VERSION ""

NS_ :

BS_:

BU_: UI BMU

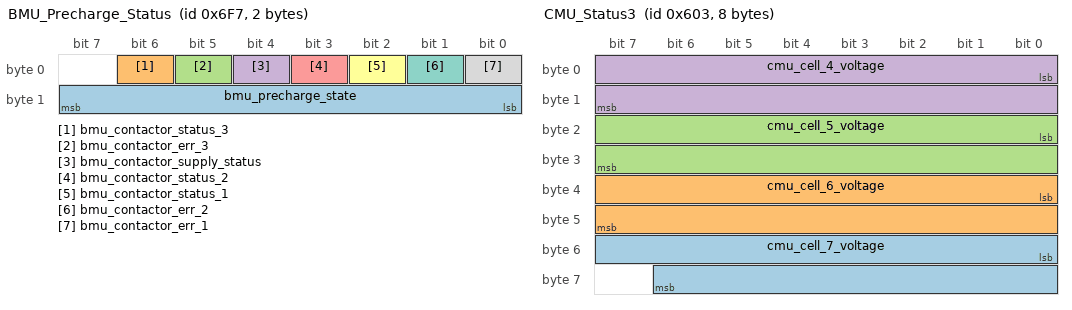
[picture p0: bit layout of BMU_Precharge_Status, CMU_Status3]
BO_ 1783 BMU_Precharge_Status: 2 BMU
 SG_ bmu_precharge_state : 8|8@1+ (1,0) [0|5] "enum" Vector__XXX
 SG_ bmu_contactor_status_3 : 6|1@1+ (1,0) [0|1] "flag" Vector__XXX
 SG_ bmu_contactor_err_3 : 5|1@1+ (1,0) [0|1] "flag" Vector__XXX
 SG_ bmu_contactor_supply_status : 4|1@1+ (1,0) [0|1] "flag" Vector__XXX
 SG_ bmu_contactor_status_2 : 3|1@1+ (1,0) [0|1] "flag" Vector__XXX
 SG_ bmu_contactor_status_1 : 2|1@1+ (1,0) [0|1] "flag" Vector__XXX
 SG_ bmu_contactor_err_2 : 1|1@1+ (1,0) [0|1] "flag" Vector__XXX
 SG_ bmu_contactor_err_1 : 0|1@1+ (1,0) [0|1] "flag" Vector__XXX

BO_ 1781 BMU_Balance_SOC: 8 BMU
 SG_ bmu_bal_soc_percent : 32|32@1- (1,0) [0|0] "%" Vector__XXX
 SG_ bmu_bal_soc_ah : 0|32@1- (1,0) [0|0] "Ah" Vector__XXX

BO_ 1780 BMU_SOC: 8 BMU
 SG_ bmu_soc_percent : 32|32@1- (1,0) [0|0] "%" Vector__XXX
 SG_ bmu_soc_ah : 0|32@1- (1,0) [0|0] "Ah" Vector__XXX

BO_ 1539 CMU_Status3: 8 BMU
 SG_ cmu_cell_7_voltage : 48|15@1- (1,0) [0|0] "mV"  UI
 SG_ cmu_cell_6_voltage : 32|16@1- (1,0) [0|0] "mV"  UI
 SG_ cmu_cell_5_voltage : 16|16@1- (1,0) [0|0] "mV"  UI
 SG_ cmu_cell_4_voltage : 0|16@1- (1,0) [0|0] "mV"  UI

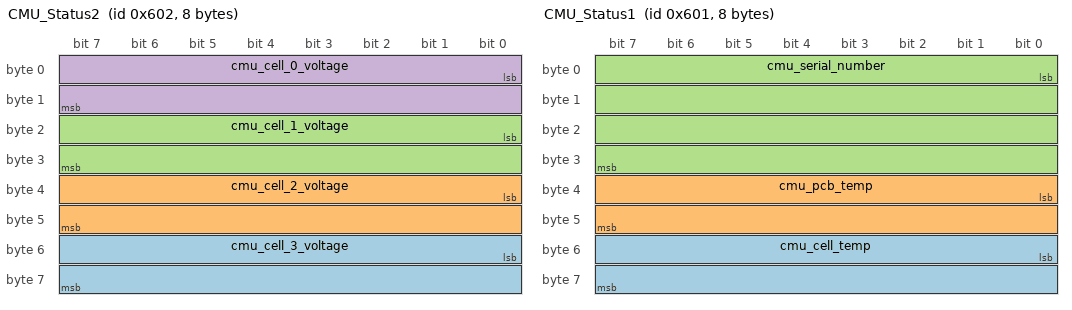
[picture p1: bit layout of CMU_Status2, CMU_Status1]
BO_ 1538 CMU_Status2: 8 BMU
 SG_ cmu_cell_3_voltage : 48|16@1- (1,0) [0|0] "mV"  UI
 SG_ cmu_cell_2_voltage : 32|16@1- (1,0) [0|0] "mV"  UI
 SG_ cmu_cell_1_voltage : 16|16@1- (1,0) [0|0] "mV"  UI
 SG_ cmu_cell_0_voltage : 0|16@1- (1,0) [0|0] "mV"  UI

BO_ 1537 CMU_Status1: 8 BMU
 SG_ cmu_cell_temp : 48|16@1- (0.1,0) [0|0] "°C"  UI
 SG_ cmu_pcb_temp : 32|16@1- (0.1,0) [0|0] "°C" Vector__XXX
 SG_ cmu_serial_number : 0|32@1+ (1,0) [0|0] "" Vector__XXX

BO_ 1536 BMU_Heartbeat: 8 BMU
 SG_ bmu_verison_number : 0|32@1+ (1,0) [0|0] "" Vector__XXX
 SG_ bmu_serial_number : 32|32@1+ (1,0) [0|0] "" Vector__XXX

EV_ test: 0 [0|0] "" 0 1 DUMMY_NODE_VECTOR0 Vector__XXX;

CM_ SG_ 1783 bmu_precharge_state "0 = Error, 1 = Idle, 5 = Enable Pack, 2 = Measure, 3 = Precharge, 4 = Run";
CM_ SG_ 1783 bmu_contactor_status_3 "0 = Off, 1 = On";
CM_ SG_ 1783 bmu_contactor_err_3 "0 = OK, 1 = error";
CM_ SG_ 1783 bmu_contactor_supply_status "0 = Fault, 1 = OK";
CM_ SG_ 1783 bmu_contactor_status_2 "0 = Off, 1 = On
";
CM_ SG_ 1783 bmu_contactor_status_1 "0 = Off, 1 = On";
CM_ SG_ 1783 bmu_contactor_err_2 "0 = OK, 1 = error";
CM_ SG_ 1783 bmu_contactor_err_1 "0 = OK, 1 = error";
CM_ SG_ 1781 bmu_bal_soc_percent "Shows the balancing SOC as a percentage, in other words, the percentage mismatch between cells this session.";
CM_ SG_ 1781 bmu_bal_soc_ah "Shows Ah supplied to the pack since the first cell began balancing. This number will continue to count up until all cells in the pack are balancing, therefore showing the Ah mismatch that has been corrected during this balancing session.";
CM_ BO_ 1780 "Interval: 1 Hz";
CM_ SG_ 1780 bmu_soc_percent "Shows the SOC as a percentage. 100% = full, 0% = empty";
CM_ SG_ 1780 bmu_soc_ah "SOC (Ah). Shows Ah consumed from the pack. 0 = Full, and counts upwards towards the user-set pack capacity number as Ah are used. Resets to 0 when max cell reaches balance threshold.";
CM_ BO_ 1539 "Interval: 1 Hz";
CM_ SG_ 1539 cmu_cell_7_voltage "+ve = OK, -ve = channel mismatch";
CM_ SG_ 1539 cmu_cell_6_voltage "+ve = OK, -ve = channel mismatch";
CM_ SG_ 1539 cmu_cell_5_voltage "+ve = OK, -ve = channel mismatch";
CM_ SG_ 1539 cmu_cell_4_voltage "+ve = OK, -ve = channel mismatch";
CM_ BO_ 1538 "Interval: 1 Hz";
CM_ SG_ 1538 cmu_cell_3_voltage "+ve = OK, -ve = channel mismatch";
CM_ SG_ 1538 cmu_cell_2_voltage "+ve = OK, -ve = channel mismatch";
CM_ SG_ 1538 cmu_cell_1_voltage "+ve = OK, -ve = channel mismatch";
CM_ SG_ 1538 cmu_cell_0_voltage "+ve = OK, -ve = channel mismatch";
CM_ BO_ 1537 "Interval: Approx 1 Hz";
CM_ SG_ 1537 cmu_cell_temp "Cell temperature ( 1/10th °C)";
CM_ SG_ 1537 cmu_pcb_temp "PCB temperature ( 1/10th °C)";
CM_ SG_ 1537 cmu_serial_number "CMU serial number (allocated at factory)";
CM_ BO_ 1536 "Interval: 1 Hz";
BA_DEF_  "BusType" STRING ;
BA_DEF_DEF_  "BusType" "CAN";
SIG_VALTYPE_ 1781 bmu_bal_soc_percent : 1;
SIG_VALTYPE_ 1781 bmu_bal_soc_ah : 1;
SIG_VALTYPE_ 1780 bmu_soc_percent : 1;
SIG_VALTYPE_ 1780 bmu_soc_ah : 1;
